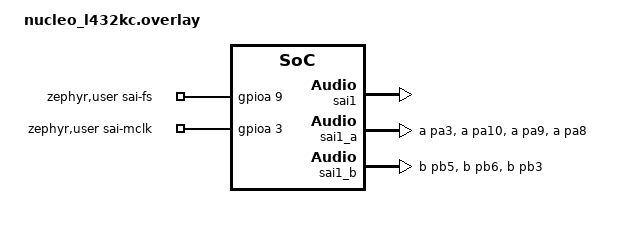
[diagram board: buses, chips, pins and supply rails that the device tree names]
/*
 * Copyright (c) 2026 Mario Paja
 *
 * SPDX-License-Identifier: Apache-2.0
 */

/ {
	aliases {
		i2s-tx = &sai1_a;
		i2s-rx = &sai1_b;
	};

	/* Pins sampled through GPIO IDR; they stay in SAI alternate function */
	zephyr,user {
		sai-fs-gpios = <&gpioa 9 0>;
		sai-mclk-gpios = <&gpioa 3 0>;
	};
};

/* 44.27KHz (0.38% Error) */
&pllsai1 {
	div-m = <1>;
	mul-n = <17>;
	div-r = <2>;
	div-q = <2>;
	div-p = <12>;
	clocks = <&clk_hsi>;
	status = "okay";
};

&dma2 {
	status = "okay";
};

&sai1 {
	status = "okay";
};

&sai1_a {
	pinctrl-0 = <&sai1_mclk_a_pa3 &sai1_sd_a_pa10
		     &sai1_fs_a_pa9 &sai1_sck_a_pa8>;
	pinctrl-names = "default";
	status = "okay";
	mclk-enable;
	mclk-divider = "div-256";
	dma-names = "tx";
};

&sai1_b {
	pinctrl-0 = <&sai1_sd_b_pb5 &sai1_fs_b_pb6 &sai1_sck_b_pb3>;
	pinctrl-names = "default";
	status = "okay";
	mclk-divider = "div-256";
	dma-names = "rx";
};

/* USART1 TX conflicts with SAI1_A FS */
&usart1 {
	status = "disabled";
};

/* I2C1 SCL conflicts with SAI1_B FS */
&i2c1 {
	status = "disabled";
};
